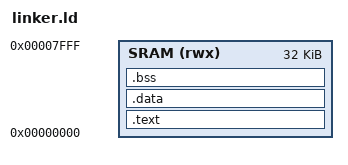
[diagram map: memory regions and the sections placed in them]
_stack_size = 4K;

MEMORY
{
    SRAM (rwx) : ORIGIN = 0x00000000, LENGTH = 32K
}

SECTIONS
{
    .text :
    {
        _text = .;
        KEEP(*(.text.start))
        *(.text.start)
        *(.text*)
        *(.rodata*)
        _etext = .;
    } > SRAM

    .data : AT(ADDR(.text) + SIZEOF(.text))
    {
        _data = .;
        *(.data*)
        _edata = .;
    } > SRAM

    .bss : AT(ADDR(.data) + SIZEOF(.data))
    {
        _bss = .;
        *(.bss*)
        *(COMMON)
        _ebss = .;
    } > SRAM


    _heap_bottom = .;
    _heap_top = ORIGIN(SRAM) + LENGTH(SRAM) - _stack_size;

    _stack_bottom = _heap_top;
    _stack_top = ORIGIN(SRAM) + LENGTH(SRAM);

}


